AUTOSAR XML (schema 4-0-3)
package /ComponentTypes
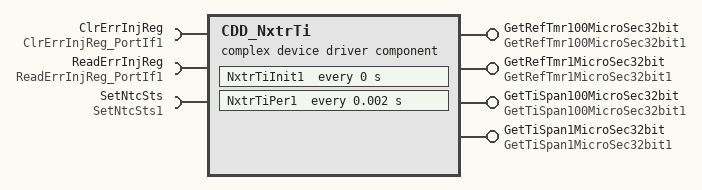
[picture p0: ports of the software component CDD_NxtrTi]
  complex device driver sw component type CDD_NxtrTi
    4 x provide port, all with server-com-spec{operation=Oper, queue-length=1}:
      GetRefTmr100MicroSec32bit: provided-interface=GetRefTmr100MicroSec32bit1
      GetRefTmr1MicroSec32bit: provided-interface=GetRefTmr1MicroSec32bit1
      GetTiSpan100MicroSec32bit: provided-interface=GetTiSpan100MicroSec32bit1
      GetTiSpan1MicroSec32bit: provided-interface=GetTiSpan1MicroSec32bit1
    require port ClrErrInjReg: client-com-spec=Oper, required-interface=ClrErrInjReg_PortIf1
    require port ReadErrInjReg: client-com-spec=Oper, required-interface=ReadErrInjReg_PortIf1
    require port SetNtcSts: client-com-spec=Oper, required-interface=SetNtcSts1
    behavior CDD_NxtrTi_InternalBehavior: data-type-mapping=Nexteer
      exclusive area NxtrTiExclusiveArea
      ar-typed-per-instance-memorys:
        data PrevTi: sw-calibration-access=READ-ONLY, type=uint32
      4 x operation invoked event:
        OIT_GetRefTmr100MicroSec32bit_Oper_GetRefTmr100MicroSec32bit_Oper: start-on-event=GetRefTmr100MicroSec32bit_Oper, operation=GetRefTmr100MicroSec32bit.Oper
        OIT_GetRefTmr1MicroSec32bit_Oper_GetRefTmr1MicroSec32bit_Oper: start-on-event=GetRefTmr1MicroSec32bit_Oper, operation=GetRefTmr1MicroSec32bit.Oper
        OIT_GetTiSpan100MicroSec32bit_Oper_GetTiSpan100MicroSec32bit_Oper: start-on-event=GetTiSpan100MicroSec32bit_Oper, operation=GetTiSpan100MicroSec32bit.Oper
        OIT_GetTiSpan1MicroSec32bit_Oper_GetTiSpan1MicroSec32bit_Oper: start-on-event=GetTiSpan1MicroSec32bit_Oper, operation=GetTiSpan1MicroSec32bit.Oper
      timing event NxtrTiInit1_InitEvent: start-on-event=NxtrTiInit1, period=0
      timing event TMT_NxtrTiPer1: start-on-event=NxtrTiPer1, period=0.002
      6 x runnable:
        GetRefTmr100MicroSec32bit_Oper: can-enter-exclusive-area=NxtrTiExclusiveArea, can-be-invoked-concurrently=true
        GetRefTmr1MicroSec32bit_Oper: can-enter-exclusive-area=NxtrTiExclusiveArea, can-be-invoked-concurrently=true
        GetTiSpan100MicroSec32bit_Oper: can-enter-exclusive-area=NxtrTiExclusiveArea, can-be-invoked-concurrently=true
        GetTiSpan1MicroSec32bit_Oper: can-enter-exclusive-area=NxtrTiExclusiveArea, can-be-invoked-concurrently=true
        NxtrTiInit1
        NxtrTiPer1: can-enter-exclusive-area=NxtrTiExclusiveArea
          sync call SC_ClrErrInjReg_Oper: operation=ClrErrInjReg.Oper, timeout=0
          sync call SC_ReadErrInjReg_Oper: operation=ReadErrInjReg.Oper, timeout=0
          sync call SC_SetNtcSts_Oper: operation=SetNtcSts.Oper, timeout=0
  swc implementation CDD_NxtrTi_Implementation: behavior=CDD_NxtrTi_InternalBehavior
    code-descriptors:
      code Default: artifact-descriptors=autosar-engineering-object={short-label=Default, category=SWSRC}
